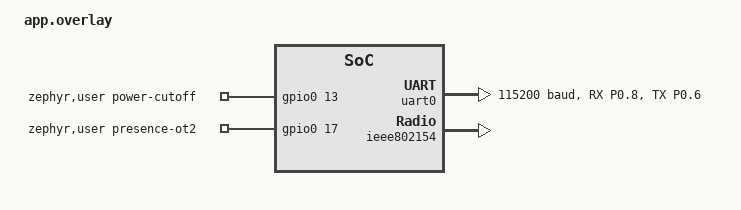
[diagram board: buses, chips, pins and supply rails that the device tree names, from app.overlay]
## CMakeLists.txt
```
# CMakeLists.txt for OpenThread SED + Home Assistant MQTT mmWave Presence Sensor (HLK-LD2410S)
cmake_minimum_required(VERSION 3.20.0)

list(APPEND BOARD_ROOT ${CMAKE_CURRENT_SOURCE_DIR})

if(EXISTS "${CMAKE_CURRENT_SOURCE_DIR}/local.conf")
    list(APPEND EXTRA_CONF_FILE "${CMAKE_CURRENT_SOURCE_DIR}/local.conf")
endif()

find_package(Zephyr HINTS $ENV{ZEPHYR_BASE})
project(presence-sensor-nrf)

target_include_directories(app PRIVATE
    src
)

target_sources(app PRIVATE
    src/main.cpp
    src/app_task.cpp
    src/battery_monitor.cpp
    src/ld2410s_proto.cpp
    src/sensor_ld2410s.cpp
    src/bthome_proto.cpp
    src/ha_mqtt_proto.cpp
    src/ota_updater.cpp
    src/thread_mqtt_publisher.cpp
    src/status_led.cpp
)

target_sources_ifdef(CONFIG_APP_DEBUG_KEEP_ALIVE app PRIVATE src/debug_fatal.c)
```

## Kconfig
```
#
# Copyright (c) 2026 Craig McLean
# OpenThread SED + Home Assistant MQTT mmWave Presence Sensor (HLK-LD2410S / HLK-LD2410C) Kconfig
#

mainmenu "OpenThread SED + Home Assistant MQTT mmWave Presence Sensor"

choice APP_RADAR_MODEL
	prompt "Hi-Link 24 GHz mmWave radar module model"
	default APP_RADAR_LD2410S

config APP_RADAR_LD2410S
	bool "HLK-LD2410S (3.3 V ultra-low-power, 115200 baud, 20x20 mm)"
	help
	  Hi-Link HLK-LD2410S 24 GHz ultra-low-power radar module powered from
	  3.3 V (P0.13 high-drive GPIO or 3V3), communicating at 115200 8N1 using
	  command 0x0070/0x007A and 5-byte minimal (6E..62) or standard frames,
	  with 0.70 m per range gate.

config APP_RADAR_LD2410C
	bool "HLK-LD2410C (5 V USB-C powered, 256000 baud, 16x22 mm)"
	help
	  Hi-Link HLK-LD2410C 24 GHz presence radar module powered from 5 V VBUS
	  (constant USB-C connection), communicating at 256000 8N1 (with automatic
	  115200 baud fallback) using command 0x0060 and standard/engineering
	  frames (F4 F3 F2 F1 .. AA .. 55 00 F8 F7 F6 F5), with 0.75 m per gate.

endchoice

config APP_ALWAYS_USB_POWERED
	bool "Device is permanently USB-powered (disable battery/SED power-saving handicaps)"
	default y if APP_RADAR_LD2410C
	default n
	help
	  Enable when the board/sensor assembly is permanently powered from 5 V USB-C.
	  Disables Sleepy End Device (SED) radio duty-cycling in favor of an always-on
	  OpenThread Minimal End Device (MED, mRxOnWhenIdle=true), keeps UART0 active
	  continuously at 100 ms (10 Hz) real-time frame polling, skips battery SAADC
	  power-gating delays, and enables wireless MQTT Firmware Over-The-Air (FOTA).

config APP_HEARTBEAT_INTERVAL_SEC
	int "Periodic idle MQTT state refresh interval (seconds)"
	default 300
	help
	  Interval between periodic Home Assistant MQTT state refreshes when no
	  occupancy edge transitions occur. Occupancy state changes are always
	  transmitted immediately via fast-polled OpenThread MQTT publish.

config APP_THREAD_DATASET_TLV_HEX
	string "OpenThread Active Operational Dataset TLV hex string"
	default ""
	help
	  Active Operational Dataset TLV hex string for the local Thread network
	  (set in gitignored local.conf; never commit network keys to git).

config APP_MQTT_BROKER_IPV4
	string "Home Assistant Mosquitto MQTT broker IPv4 address (translated via NAT64)"
	default "192.168.41.250"
	help
	  IPv4 address of the Home Assistant MQTT broker. Translated to an IPv6
	  address at runtime using the OpenThread Border Router's /96 NAT64 prefix.

config APP_MQTT_BROKER_PORT
	int "Home Assistant MQTT broker TCP port"
	range 1 65535
	default 1883
	help
	  TCP port of the Home Assistant Mosquitto MQTT broker.

config APP_MQTT_USERNAME
	string "Home Assistant MQTT broker username"
	default ""
	help
	  MQTT broker username (set in gitignored local.conf).

config APP_MQTT_PASSWORD
	string "Home Assistant MQTT broker password"
	default ""
	help
	  MQTT broker password (set in gitignored local.conf; never commit to git).

config APP_MQTT_KEEPALIVE_SEC
	int "MQTT keepalive interval (seconds)"
	range 30 3600
	default 300
	help
	  MQTT keepalive interval in seconds for the persistent TCP/NAT64 session.

config APP_RADAR_POLL_INTERVAL_MS
	int "Fast UART radar poll interval for sub-second presence & distance updates (ms)"
	range 100 10000
	default 400
	help
	  Periodic interval in milliseconds at which uart0 wakes briefly (~60 ms at
	  8.0 Hz radar report rate) to sample HLK-LD2410S presence, motion, and
	  distance. Enables < 300 ms bathroom light-trigger latency even on 4-wire
	  hookups where OT2 (P0.17) is not wired.

config APP_OCCUPIED_DISTANCE_POLL_SEC
	int "Occupied target distance refresh interval (seconds)"
	range 1 300
	default 5
	help
	  Legacy/background seconds-granularity poll interval when OT2 is wired.

config APP_BATTERY_SAMPLE_INTERVAL_SEC
	int "Battery voltage sampling interval (seconds)"
	default 3600
	help
	  Interval between SAADC VDDH/5 battery voltage measurements.

config APP_RADAR_MAX_GATE
	int "HLK-LD2410S farthest detection distance gate (0.7 m per gate)"
	range 1 16
	default 3
	help
	  Sets the HLK-LD2410S farthest detection gate (0.70 m per gate).
	  Gate 3 = 2.10 m, sized for a ~3 m^3 bathroom (~1.5 x 1.5 x 2.2 m) so
	  radar energy does not penetrate drywall or doors into adjacent hallways.

config APP_RADAR_MIN_GATE
	int "HLK-LD2410S nearest detection distance gate"
	range 0 15
	default 0
	help
	  Sets the HLK-LD2410S nearest detection gate (0 = 0.0 m).

config APP_RADAR_MAX_DISTANCE_MM
	int "Maximum valid target distance boundary (mm)"
	range 500 6000
	default 2950 if APP_RADAR_LD2410C
	default 2100
	help
	  Clamps radar targets beyond this distance (mm) to Unoccupied so far-wall
	  or hallway reflections beyond the room boundary are ignored (2950 mm for
	  a 3.0 m office with HLK-LD2410C; 2100 mm for a 3 m^3 bathroom with LD2410S).

config APP_RADAR_HOLD_S
	int "Unoccupied delay / hold time (seconds)"
	range 10 600
	default 180 if APP_RADAR_LD2410C
	default 30
	help
	  Time in seconds occupancy remains asserted after the last detected motion
	  or breathing signature clears (180 s default for seated office desk work on
	  HLK-LD2410C; 30 s default for walk-in bathroom on HLK-LD2410S).

choice APP_BATTERY_SENSE
	prompt "Battery voltage sense method"
	default APP_BATTERY_SENSE_VDDH

config APP_BATTERY_SENSE_VDDH
	bool "Internal VDDH/5"
	help
	  Use when the 18650 cell is wired to the B+/BAT pad, which feeds the
	  nRF52840 VDDH pin directly (nice!nano v2 and SuperMini). No external
	  parts. Note that on the SuperMini VDDH rises while USB is charging.

config APP_BATTERY_SENSE_DIVIDER
	bool "External resistor divider on an analog input"
	help
	  The SuperMini's on-board divider is wired to P0.24, which is not an
	  analog input, so this needs an external divider.

endchoice

if APP_BATTERY_SENSE_DIVIDER

config APP_BATTERY_DIVIDER_AIN
	int "SAADC analog input (AINx) the divider midpoint is wired to"
	range 0 7
	default 5
	help
	  AIN0=P0.02 AIN1=P0.03 AIN2=P0.04 AIN3=P0.05
	  AIN4=P0.28 AIN5=P0.29 AIN6=P0.30 AIN7=P0.31

config APP_BATTERY_DIVIDER_R_TOP_OHMS
	int "Divider resistor from battery to midpoint (ohms)"
	default 806000

config APP_BATTERY_DIVIDER_R_BOTTOM_OHMS
	int "Divider resistor from midpoint to GND (ohms)"
	default 2000000

endif # APP_BATTERY_SENSE_DIVIDER

config APP_DEBUG_KEEP_ALIVE
	bool "Keep running after fatal errors, asserts and abort() (debug only)"
	help
	  Aborts only the failing thread so its error report can still be
	  logged. Never enable in a deployed build.

source "Kconfig.zephyr"
```

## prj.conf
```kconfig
# OpenThread SED + Home Assistant MQTT mmWave Presence Sensor (HLK-LD2410S) Configuration
CONFIG_CPP=y
CONFIG_STD_CPP20=y
CONFIG_REQUIRES_FULL_LIBCPP=y

# Hardware Peripherals
CONFIG_GPIO=y
CONFIG_SERIAL=y
CONFIG_UART_INTERRUPT_DRIVEN=y
CONFIG_ADC=y
CONFIG_ADC_NRFX_SAADC=y
CONFIG_HWINFO=y

# Power Management (suspends uart0 UARTE0 between radar distance reads via pm_device_action_run;
# keep CONFIG_PM_DEVICE_RUNTIME=n so uarte_nrfx_isr_int does not call nrf_uarte_disable on RX IRQ)
CONFIG_PM_DEVICE=y
CONFIG_PM_DEVICE_RUNTIME=n
CONFIG_POWEROFF=y

# Logging & console disabled in release builds for battery life.
# uart0 is used exclusively for HLK-LD2410S communication and is suspended
# via PM_DEVICE_ACTION_SUSPEND during idle sleep.
# For bring-up logs over USB CDC ACM, build with:
#   -DEXTRA_CONF_FILE=debug.conf -DEXTRA_DTC_OVERLAY_FILE=debug.overlay
CONFIG_LOG=n
CONFIG_CONSOLE=n
CONFIG_UART_CONSOLE=n
CONFIG_BOOT_BANNER=n

# System Stacks & Heap (sized for OpenThread SED + IPv6/TCP + MQTT)
CONFIG_MAIN_STACK_SIZE=6144
CONFIG_SYSTEM_WORKQUEUE_STACK_SIZE=4096
CONFIG_HEAP_MEM_POOL_SIZE=16384

# Flash, NVS & Bootloader Output (UF2 at 0x1000 for nice!nano v2 / SuperMini nRF52840)
CONFIG_BOOTLOADER_MCUBOOT=n
CONFIG_BUILD_OUTPUT_UF2=y
CONFIG_BUILD_OUTPUT_HEX=y
CONFIG_USE_DT_CODE_PARTITION=y
CONFIG_FLASH=y
CONFIG_FLASH_PAGE_LAYOUT=y
CONFIG_FLASH_MAP=y
CONFIG_NVS=y
CONFIG_SETTINGS=y
CONFIG_SETTINGS_NVS=y

# OpenThread 1.3 Sleepy End Device (SED) + NAT64 + Home Assistant MQTT over IPv6/TCP
CONFIG_BT=n
CONFIG_NETWORKING=y
CONFIG_NET_L2_OPENTHREAD=y
CONFIG_OPENTHREAD_NORDIC_LIBRARY_COMMON=y
CONFIG_OPENTHREAD_THREAD_VERSION_1_3=y
CONFIG_OPENTHREAD_MTD=y
CONFIG_OPENTHREAD_MTD_SED=y
CONFIG_OPENTHREAD_POLL_PERIOD=5000
CONFIG_OPENTHREAD_DEFAULT_TX_POWER=8
CONFIG_OPENTHREAD_MANUAL_START=y
CONFIG_OPENTHREAD_DNS_CLIENT=y
CONFIG_OPENTHREAD_CUSTOM_PARAMETERS="OPENTHREAD_CONFIG_NAT64_CLIENT_ENABLE=1"

CONFIG_NET_IPV6=y
CONFIG_NET_IPV4=n
CONFIG_NET_IPV6_NBR_CACHE=n
CONFIG_NET_IPV6_MLD=n
CONFIG_NET_TCP=y
CONFIG_NET_UDP=y
CONFIG_NET_SOCKETS=y
CONFIG_MQTT_LIB=y
CONFIG_NET_PKT_RX_COUNT=32
CONFIG_NET_PKT_TX_COUNT=32
CONFIG_NET_BUF_RX_COUNT=64
CONFIG_NET_BUF_TX_COUNT=64

# Hardening & Diagnostics
CONFIG_RESET_ON_FATAL_ERROR=y
CONFIG_THREAD_NAME=y
CONFIG_MPU_STACK_GUARD=y
```

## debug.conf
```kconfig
# Debug overlay: logs over a USB CDC ACM serial port (no USB-serial adapter needed).
# Keeps the USB peripheral and logging active - several hundred uA, do not deploy on battery.
# Usage: west build ... -- -DEXTRA_CONF_FILE=debug.conf -DEXTRA_DTC_OVERLAY_FILE=debug.overlay
# On macOS: screen /dev/cu.usbmodem* 115200
CONFIG_USB_DEVICE_STACK=y
CONFIG_USB_DEVICE_INITIALIZE_AT_BOOT=y
CONFIG_USB_DEVICE_PRODUCT="Presence Sensor Debug"
CONFIG_USB_DEVICE_PID=0x0002
CONFIG_USB_DEVICE_LOG_LEVEL_OFF=y
CONFIG_USB_CDC_ACM_LOG_LEVEL_OFF=y
CONFIG_SERIAL=y
CONFIG_UART_LINE_CTRL=y
CONFIG_CONSOLE=y
CONFIG_UART_CONSOLE=y
CONFIG_PRINTK=y
CONFIG_LOG=y
CONFIG_LOG_MODE_DEFERRED=y
CONFIG_LOG_DEFAULT_LEVEL=3
CONFIG_APP_DEBUG_KEEP_ALIVE=y
CONFIG_RESET_ON_FATAL_ERROR=n
CONFIG_LOG_BUFFER_SIZE=16384
CONFIG_CBPRINTF_FP_SUPPORT=y
```

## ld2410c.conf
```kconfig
#
# Copyright (c) 2026 Craig McLean
# Overlay configuration for Hi-Link HLK-LD2410C (5 V USB-C powered, 256000 baud, 16x22 mm)
#
# Build with:
#   west build --no-sysbuild -b nice_nano/nrf52840 -p always -- -DEXTRA_CONF_FILE="local.conf;ld2410c.conf"
#

CONFIG_APP_RADAR_LD2410C=y
CONFIG_APP_ALWAYS_USB_POWERED=y

# Always-on OpenThread Minimal End Device (MED: RxOnWhenIdle=true, zero sleepy parent-poll latency)
CONFIG_OPENTHREAD_MTD_SED=n

# 10 Hz (100 ms) real-time radar processing matching HLK-LD2410C native 10 Hz output rate
CONFIG_APP_RADAR_POLL_INTERVAL_MS=100

# Office geometry: 3.0 m max wall distance (0-indexed Gates 0..3 = 0.00..3.00 m), ~1.0 m seated desk position, 180 s (3 min) hold
CONFIG_APP_RADAR_MAX_GATE=3
CONFIG_APP_RADAR_MAX_DISTANCE_MM=2950
CONFIG_APP_RADAR_HOLD_S=180

# 180 s MQTT keepalive on always-powered Thread MED (tolerates transient 6LoWPAN/NAT64 jitter)
CONFIG_APP_MQTT_KEEPALIVE_SEC=180

# Enable flash write access for wireless MQTT FOTA self-update
CONFIG_MPU_ALLOW_FLASH_WRITE=y
```

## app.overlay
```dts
/*
 * Copyright (c) 2026 Craig McLean
 * Devicetree overlay for BTHome v2 BLE mmWave Presence Sensor (HLK-LD2410S)
 *
 * Pinout on SuperMini nRF52840 (nice!nano v2 clone):
 *   - P0.13 (VCC switch): Continuous 3.3V supply to HLK-LD2410S (cut off at <= 3.0V)
 *   - P0.17 (017 / D2):   HLK-LD2410S OT2 digital presence output (GPIO_INT_EDGE_BOTH)
 *   - P0.08 (008 / D0):   uart0 RX <- HLK-LD2410S TX (115200 8N1)
 *   - P0.06 (006 / D1):   uart0 TX -> HLK-LD2410S RX (115200 8N1)
 */

/ {
    chosen {
        /delete-property/ zephyr,console;
        /delete-property/ zephyr,shell-uart;
        /delete-property/ zephyr,uart-mcumgr;
        zephyr,ieee802154 = &ieee802154;
        zephyr,settings-partition = &storage_partition;
    };

    zephyr,user {
        /* External VCC Power Cutoff: Pin 13 (P0.13), held HIGH in System ON */
        power-cutoff-gpios = <&gpio0 13 GPIO_ACTIVE_HIGH>;
        /* HLK-LD2410S OT2 Presence Pin: P0.17 (D2), active HIGH with pull-down */
        presence-ot2-gpios = <&gpio0 17 (GPIO_ACTIVE_HIGH | GPIO_PULL_DOWN)>;
    };
};

/*
 * Explicit uart0 pinctrl matching soldered wiring:
 *   - P0.08 (008 / D0): UART_RX <- HLK-LD2410S OT1 (TX)
 *   - P0.06 (006 / D1): UART_TX -> HLK-LD2410S RX
 */
&pinctrl {
    uart0_default: uart0_default {
        group1 {
            psels = <NRF_PSEL(UART_RX, 0, 8)>;
            bias-pull-up;
        };
        group2 {
            psels = <NRF_PSEL(UART_TX, 0, 6)>;
        };
    };

    uart0_sleep: uart0_sleep {
        group1 {
            psels = <NRF_PSEL(UART_RX, 0, 8)>,
                    <NRF_PSEL(UART_TX, 0, 6)>;
            low-power-enable;
        };
    };
};

/*
 * HLK-LD2410S UART interface (115200 8N1 on P0.06 TX / P0.08 RX).
 * Explicitly suspended via pm_device_action_run(PM_DEVICE_ACTION_SUSPEND)
 * during System ON sleep so UARTE0 and the 64 MHz HFCLK draw 0 uA when idle.
 */
&uart0 {
    compatible = "nordic,nrf-uarte";
    status = "okay";
    current-speed = <115200>;
    pinctrl-0 = <&uart0_default>;
    pinctrl-1 = <&uart0_sleep>;
    pinctrl-names = "default", "sleep";
};

/* Disable unused peripherals for minimal sleep leakage */
&i2c0 {
    status = "disabled";
};

/* Enable IEEE 802.15.4 radio for OpenThread Sleepy End Device (SED) */
&ieee802154 {
    status = "okay";
};
```

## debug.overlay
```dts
/* Debug overlay: route the console and logs to a USB CDC ACM serial port. Use with debug.conf. */
/ {
    chosen {
        zephyr,console = &cdc_acm_uart0;
    };
};

&zephyr_udc0 {
    status = "okay";
    cdc_acm_uart0: cdc_acm_uart0 {
        compatible = "zephyr,cdc-acm-uart";
    };
};
```

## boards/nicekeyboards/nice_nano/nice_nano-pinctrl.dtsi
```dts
/*
 * Pin control configuration for nice!nano v2 / SuperMini nRF52840
 */

&pinctrl {
    uart0_default: uart0_default {
        group1 {
            psels = <NRF_PSEL(UART_RX, 0, 8)>;
            bias-pull-up;
        };
        group2 {
            psels = <NRF_PSEL(UART_TX, 0, 6)>;
        };
    };

    uart0_sleep: uart0_sleep {
        group1 {
            psels = <NRF_PSEL(UART_RX, 0, 8)>,
                   <NRF_PSEL(UART_TX, 0, 6)>;
            low-power-enable;
        };
    };

    i2c0_default: i2c0_default {
        group1 {
            psels = <NRF_PSEL(TWIM_SDA, 0, 17)>,
                   <NRF_PSEL(TWIM_SCL, 0, 20)>;
            bias-pull-up;
        };
    };

    i2c0_sleep: i2c0_sleep {
        group1 {
            psels = <NRF_PSEL(TWIM_SDA, 0, 17)>,
                   <NRF_PSEL(TWIM_SCL, 0, 20)>;
            low-power-enable;
        };
    };

    spi1_default: spi1_default {
        group1 {
            psels = <NRF_PSEL(SPIM_SCK, 1, 13)>,
                   <NRF_PSEL(SPIM_MOSI, 0, 10)>,
                   <NRF_PSEL(SPIM_MISO, 1, 11)>;
        };
    };

    spi1_sleep: spi1_sleep {
        group1 {
            psels = <NRF_PSEL(SPIM_SCK, 1, 13)>,
                   <NRF_PSEL(SPIM_MOSI, 0, 10)>,
                   <NRF_PSEL(SPIM_MISO, 1, 11)>;
            low-power-enable;
        };
    };
};
```

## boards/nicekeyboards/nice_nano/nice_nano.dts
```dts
/*
 * Copyright (c) 2026 Craig McLean
 * Board Devicetree for nice!nano v2 / SuperMini nRF52840
 */

/dts-v1/;

#include <nordic/nrf52840_qiaa.dtsi>
#include "nice_nano-pinctrl.dtsi"

/ {
    model = "nice!nano v2 / SuperMini nRF52840";
    compatible = "nicekeyboards,nice_nano", "nordic,nrf52840-qiaa", "nordic,nrf52840";

    chosen {
        zephyr,code-partition = &code_partition;
        zephyr,sram = &sram0;
        zephyr,flash = &flash0;
        zephyr,console = &uart0;
        zephyr,shell-uart = &uart0;
        zephyr,uart-mcumgr = &uart0;
        zephyr,ieee802154 = &ieee802154;
    };

    leds {
        compatible = "gpio-leds";
        blue_led: led_0 {
            gpios = <&gpio0 15 GPIO_ACTIVE_HIGH>;
            label = "Blue LED";
        };
    };

    buttons {
        compatible = "gpio-keys";
    };

    aliases {
        led0 = &blue_led;
    };

    zephyr,user {
        /* External VCC Power Cutoff: Pin 13 (P0.13) */
        power-cutoff-gpios = <&gpio0 13 GPIO_ACTIVE_HIGH>;
    };
};

/*
 * REG1 is left in its default LDO mode. DC/DC mode needs an inductor on DCC,
 * which is not confirmed on SuperMini clones; enabling it without one stops
 * the SoC from running. With the radio mostly asleep the saving is ~1-2 uA.
 */

/* Battery channel is configured at runtime (see battery_monitor.cpp / Kconfig) */
&adc {
    status = "okay";
};

&gpiote {
    status = "okay";
};

&gpio0 {
    status = "okay";
};

&gpio1 {
    status = "okay";
};

&i2c0 {
    compatible = "nordic,nrf-twim";
    status = "okay";
    pinctrl-0 = <&i2c0_default>;
    pinctrl-1 = <&i2c0_sleep>;
    pinctrl-names = "default", "sleep";
    clock-frequency = <I2C_BITRATE_STANDARD>;
    zephyr,pm-device-runtime-auto;
};

/*
 * Disabled for battery life: an active UARTE receiver keeps the HF clock
 * running (hundreds of uA). debug.overlay re-enables it for logging.
 */
&uart0 {
    compatible = "nordic,nrf-uarte";
    status = "disabled";
    current-speed = <115200>;
    pinctrl-0 = <&uart0_default>;
    pinctrl-1 = <&uart0_sleep>;
    pinctrl-names = "default", "sleep";
};

/*
 * Disabled for battery life: debug.overlay re-enables it for USB logging.
 */
zephyr_udc0: &usbd {
    status = "disabled";
};

&ieee802154 {
    status = "okay";
};

&flash0 {
    partitions {
        compatible = "fixed-partitions";
        #address-cells = <1>;
        #size-cells = <1>;

        /*
         * This board's Adafruit UF2 bootloader (0.6.1) reports "SoftDevice: not
         * found" in INFO_UF2.TXT; without a SoftDevice it starts the app right
         * after the MBR at 0x1000. On a board whose INFO_UF2.TXT lists
         * "SoftDevice: S140 6.1.1" the app must start at 0x26000 instead.
         */
        mbr_partition: partition@0 {
            label = "mbr";
            reg = <0x00000000 0x00001000>;
        };

        code_partition: partition@1000 {
            label = "code_partition";
            reg = <0x00001000 0x000eb000>;
        };

        storage_partition: partition@ec000 {
            label = "storage";
            reg = <0x000ec000 0x00008000>;
        };

        boot_partition: partition@f4000 {
            label = "adafruit_boot";
            reg = <0x000f4000 0x0000c000>;
        };
    };
};
```

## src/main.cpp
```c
/*
 * Copyright (c) 2026 Craig McLean
 * Main Application Entry Point
 */

#include "app_task.h"
#include "status_led.h"
#include "version.h"
#include <zephyr/logging/log.h>

#if DT_NODE_HAS_COMPAT(DT_CHOSEN(zephyr_console), zephyr_cdc_acm_uart)
#include <zephyr/drivers/uart.h>
#endif

LOG_MODULE_REGISTER(app, LOG_LEVEL_INF);

int main()
{
    // First thing: solid 500 ms flash proves the application (not the UF2 bootloader) is running
    StatusLed::Instance().Init();

#if DT_NODE_HAS_COMPAT(DT_CHOSEN(zephyr_console), zephyr_cdc_acm_uart)
    // Debug build with USB console: wait (up to 10 s) for a terminal to open
    // the port so early boot logs are not lost
    const struct device *console = DEVICE_DT_GET(DT_CHOSEN(zephyr_console));
    for (int i = 0; i < 100; i++) {
        uint32_t dtr = 0;
        if (uart_line_ctrl_get(console, UART_LINE_CTRL_DTR, &dtr) == 0 && dtr) {
            break;
        }
        k_msleep(100);
    }
#endif

    LOG_INF("=========================================================");
    LOG_INF("  OpenThread SED + HA MQTT Presence Sensor v%s (SuperMini nRF52840)", APP_VERSION_STRING);
    LOG_INF("=========================================================");

    int ret = AppTask::Instance().Start();
    if (ret != 0) {
        LOG_ERR("AppTask start failed with error: %d", ret);
        return ret;
    }

    while (true) {
        k_sleep(K_FOREVER);
    }

    return 0;
}
```

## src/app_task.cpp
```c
/*
 * Copyright (c) 2026 Craig McLean
 * Application Task & Low-Power Event Loop (HLK-LD2410S + OpenThread SED + Home Assistant MQTT)
 */

#include "app_task.h"
#include "status_led.h"
#include "version.h"
#include <zephyr/logging/log.h>

LOG_MODULE_REGISTER(app_task, LOG_LEVEL_INF);

namespace {

static constexpr uint32_t kEvtOt2Edge                      = BIT(0);
static constexpr uint32_t kEvtOccupiedPoll                 = BIT(1);
static constexpr uint32_t kEvtHeartbeat                    = BIT(2);
static constexpr uint32_t kEvtBatterySample                = BIT(3);
static constexpr uint32_t kEvtBurstDone                    = BIT(4);
static constexpr uint16_t kDistanceBurstThresholdMm        = 150u;
static constexpr int64_t  kMinDistancePublishIntervalMs    = 1500;
static constexpr int64_t  kPostTransitionReassertWindowMs  = 15000;
static constexpr int64_t  kPostTransitionReassertPeriodMs  = 3200;

} // namespace

AppTask::AppTask()
    : mBatteryStatus{BatteryMonitor::VOLTAGE_NOMINAL_MV, 50, BatteryChargeLevel::OK, false},
      mLastRadarReport{Ld2410sTargetState::Unoccupied, false, false, 0, 0, true, false, 0, 0, 0, 0, 0, 0},
      mPendingEvents(ATOMIC_INIT(0)),
      mLastStateChangeMs(0),
      mLastPublishMs(0),
      mLastPublishedDistanceMm(0u),
      mLastOccupied(false),
      mLastMotion(false)
{
}

void AppTask::OnOt2EdgeStatic()
{
    Instance().NotifyOt2Edge();
}

void AppTask::OnHeartbeatTimer(struct k_timer *timer)
{
    ARG_UNUSED(timer);
    Instance().PostEvent(kEvtHeartbeat);
}

void AppTask::OnOccupiedPollTimer(struct k_timer *timer)
{
    ARG_UNUSED(timer);
    Instance().PostEvent(kEvtOccupiedPoll);
}

void AppTask::OnBatteryTimer(struct k_timer *timer)
{
    ARG_UNUSED(timer);
    Instance().PostEvent(kEvtBatterySample);
}

void AppTask::PostEvent(uint32_t eventMask)
{
    atomic_or(&mPendingEvents, static_cast<atomic_val_t>(eventMask));
    k_sem_give(&mEventSem);
}

void AppTask::NotifyOt2Edge()
{
    PostEvent(kEvtOt2Edge);
}

void AppTask::NotifyBurstComplete()
{
    PostEvent(kEvtBurstDone);
}

void AppTask::SampleBattery()
{
    BatteryStatus status{};
    if (BatteryMonitor::Instance().ReadBatteryStatus(&status) == 0) {
        mBatteryStatus = status;
    }
}

void AppTask::PublishCurrentState(bool burst)
{
    const BthomeMeasurement m = {
        .packetId   = 0, // Auto-incremented inside ThreadMqttPublisher::Publish
        .batteryPct = mBatteryStatus.percentRemaining,
        .voltageMv  = mBatteryStatus.voltageMv,
        .motion     = mLastRadarReport.motion,
        .occupancy  = mLastRadarReport.occupied,
        .distanceMm = mLastRadarReport.distanceMm,
    };

    mLastPublishMs = k_uptime_get();
    (void)mPublisher.Publish(m, burst);
}

void AppTask::HandleOt2AndDistanceUpdate(bool forceBurst, bool forcePublish)
{
    Ld2410sReport report{};
    mRadar.SampleTargetReport(&report);

    const int64_t nowMs = k_uptime_get();
    static constexpr uint16_t kMaxDistanceMm =
        static_cast<uint16_t>(CONFIG_APP_RADAR_MAX_DISTANCE_MM);
    static constexpr int64_t kOccupancyHoldWindowMs =
        static_cast<int64_t>(CONFIG_APP_RADAR_HOLD_S) * 1000;
    mMotionTracker.Update(&report, nowMs, kMaxDistanceMm, kOccupancyHoldWindowMs);
    mLastRadarReport = report;

    const Ld2410sReport rawReport = mRadar.GetLastValidReport();
    mPublisher.UpdateRadarDiag({
        .rawState         = rawReport.rawState,
        .movingEnergy     = rawReport.movingEnergy,
        .stationaryEnergy = rawReport.stationaryEnergy,
        .movingDistCm     = rawReport.movingDistanceCm,
        .stationaryDistCm = rawReport.stationaryDistanceCm,
        .detectionDistCm  = rawReport.detectionDistanceCm,
        .rxBytes          = mRadar.GetRxBytesSeen(),
        .configured       = mRadar.IsRadarConfigured(),
        .occupied         = report.occupied,
        .motion           = report.motion,
    });

    const bool stateChanged = (report.occupied != mLastOccupied) ||
                              (report.motion != mLastMotion);
    const bool occupancyEdge = (report.occupied != mLastOccupied);
    const uint16_t distDeltaMm = (report.distanceMm > mLastPublishedDistanceMm)
                                     ? (report.distanceMm - mLastPublishedDistanceMm)
                                     : (mLastPublishedDistanceMm - report.distanceMm);
    const bool significantDistChange =
        report.occupied &&
        (distDeltaMm >= kDistanceBurstThresholdMm) &&
        ((nowMs - mLastPublishMs) >= kMinDistancePublishIntervalMs);

    if (stateChanged) {
        mLastStateChangeMs = nowMs;
        mRadar.LogDiagnostics(report, forceBurst ? "ot2-edge" : "state-chg");
    } else if (forceBurst) {
        mRadar.LogDiagnostics(report, "ot2-edge");
    } else {
        static int64_t sLastDiagLogMs = 0;
        if ((nowMs - sLastDiagLogMs) >= 2000) {
            sLastDiagLogMs = nowMs;
            mRadar.LogDiagnostics(report, "diag-2s");
        }
    }

    // Re-assert recent occupancy/motion transitions every 3.2 s for 15 s on battery/SED builds;
    // skipped on always-USB-powered Thread MED builds where TCP/MQTT delivery is continuous.
    const bool shouldReassertTransition =
        !IS_ENABLED(CONFIG_APP_ALWAYS_USB_POWERED) &&
        (mLastStateChangeMs > 0) &&
        ((nowMs - mLastStateChangeMs) <= kPostTransitionReassertWindowMs) &&
        ((nowMs - mLastPublishMs) >= kPostTransitionReassertPeriodMs);

    mLastOccupied = report.occupied;
    mLastMotion   = report.motion;

    const bool shouldBurst = forceBurst ||
                             occupancyEdge ||
                             stateChanged ||
                             significantDistChange ||
                             shouldReassertTransition;
    if (shouldBurst || forcePublish) {
        mLastPublishedDistanceMm = report.distanceMm;
        PublishCurrentState(shouldBurst);
    }
}

int AppTask::Start()
{
    LOG_INF("Starting OpenThread SED + Home Assistant MQTT mmWave Presence Sensor v%s (build %d)",
            APP_VERSION_STRING, APP_BUILD_NUMBER);

    k_sem_init(&mEventSem, 0, K_SEM_MAX_LIMIT);
    k_timer_init(&mHeartbeatTimer, OnHeartbeatTimer, nullptr);
    k_timer_init(&mOccupiedPollTimer, OnOccupiedPollTimer, nullptr);
    k_timer_init(&mBatteryTimer, OnBatteryTimer, nullptr);

    // 1. Initialize Battery Monitor with P0.13 LOW (radar unpowered) and configure SAADC VDDH/5
    int ret = BatteryMonitor::Instance().Init();
    if (ret != 0) {
        LOG_ERR("BatteryMonitor::Init failed (err: %d)", ret);
        StatusLed::Instance().BlinkError(2);
    }

    // Read initial unloaded battery/VBUS voltage before enabling the radar 3.3 V rail
    SampleBattery();

    // 2. Initialize OpenThread Sleepy End Device (SED) + Home Assistant MQTT Publisher
    ret = mPublisher.Init();
    if (ret != 0) {
        LOG_ERR("ThreadMqttPublisher::Init failed (err: %d)", ret);
        StatusLed::Instance().BlinkError(4);
        return ret;
    }
    PublishCurrentState(true);

    // 3. Enable P0.13 3.3 V VCC rail and initialize HLK-LD2410S (P0.17 OT2 + uart0 config + auto pin-swap probe)
    (void)BatteryMonitor::Instance().SetSensorPower(true);
    ret = mRadar.Init(OnOt2EdgeStatic);
    if (ret != 0) {
        LOG_ERR("SensorLd2410s::Init failed (err: %d)", ret);
        StatusLed::Instance().BlinkError(3);
    }

    // Ensure P0.15 status LED is strictly OFF before entering the low-power event loop
    StatusLed::Instance().Set(false);

    // 4. Perform initial radar sample and queue/publish updated state
    HandleOt2AndDistanceUpdate(true, true);

    // 5. Start periodic low-power timers (400 ms sub-second radar UART poll + heartbeat + battery)
    k_timer_start(&mOccupiedPollTimer,
                   K_MSEC(CONFIG_APP_RADAR_POLL_INTERVAL_MS),
                   K_MSEC(CONFIG_APP_RADAR_POLL_INTERVAL_MS));
    k_timer_start(&mHeartbeatTimer,
                   K_SECONDS(CONFIG_APP_HEARTBEAT_INTERVAL_SEC),
                   K_SECONDS(CONFIG_APP_HEARTBEAT_INTERVAL_SEC));
    k_timer_start(&mBatteryTimer,
                   K_SECONDS(CONFIG_APP_BATTERY_SAMPLE_INTERVAL_SEC),
                   K_SECONDS(CONFIG_APP_BATTERY_SAMPLE_INTERVAL_SEC));

    LOG_INF("Entering System ON low-power event loop (poll=%dms, heartbeat=%ds, battery=%ds)",
            CONFIG_APP_RADAR_POLL_INTERVAL_MS,
            CONFIG_APP_HEARTBEAT_INTERVAL_SEC,
            CONFIG_APP_BATTERY_SAMPLE_INTERVAL_SEC);

    while (true) {
        k_sem_take(&mEventSem, K_FOREVER);

        const uint32_t events = static_cast<uint32_t>(atomic_clear(&mPendingEvents));

        if (events & kEvtBatterySample) {
            SampleBattery();
        }

        const bool forceBurst   = (events & kEvtOt2Edge) != 0u;
        const bool forcePublish = (events & kEvtHeartbeat) != 0u;

        if (events & (kEvtOt2Edge | kEvtOccupiedPoll)) {
            HandleOt2AndDistanceUpdate(forceBurst, forcePublish);
        } else if (forcePublish) {
            PublishCurrentState(false);
        }

        // Flush any queued boot/reconnect publish once Thread attaches and service MQTT keepalive
        mPublisher.ProcessBackground();
    }

    return 0;
}
```

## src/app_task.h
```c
/*
 * Copyright (c) 2026 Craig McLean
 * Application Task & Low-Power Event Loop (HLK-LD2410S + OpenThread SED + HA MQTT)
 */

#pragma once

#include <zephyr/kernel.h>
#include <zephyr/sys/atomic.h>
#include "battery_monitor.h"
#include "sensor_ld2410s.h"
#include "thread_mqtt_publisher.h"

class AppTask {
public:
    static AppTask &Instance() {
        static AppTask sInstance;
        return sInstance;
    }

    /**
     * @brief Initialize peripherals, OpenThread SED + HA MQTT publisher, and run the low-power event loop.
     */
    int Start();

    /**
     * @brief Signal from ISR or timer context that an OT2 GPIO edge occurred.
     */
    void NotifyOt2Edge();

    /**
     * @brief Signal from timer context that a burst window completed.
     */
    void NotifyBurstComplete();

private:
    AppTask();

    static void OnOt2EdgeStatic();
    static void OnHeartbeatTimer(struct k_timer *timer);
    static void OnOccupiedPollTimer(struct k_timer *timer);
    static void OnBatteryTimer(struct k_timer *timer);

    void PostEvent(uint32_t eventMask);
    void HandleOt2AndDistanceUpdate(bool forceBurst, bool forcePublish = false);
    void SampleBattery();
    void PublishCurrentState(bool burst);

    SensorLd2410s        mRadar;
    ThreadMqttPublisher  mPublisher;
    BatteryStatus        mBatteryStatus;
    Ld2410sReport        mLastRadarReport;
    Ld2410sMotionTracker mMotionTracker;
    struct k_sem         mEventSem;
    atomic_t           mPendingEvents;
    struct k_timer     mHeartbeatTimer;
    struct k_timer     mOccupiedPollTimer;
    struct k_timer     mBatteryTimer;
    int64_t            mLastStateChangeMs;
    int64_t            mLastPublishMs;
    uint16_t           mLastPublishedDistanceMm;
    bool               mLastOccupied;
    bool               mLastMotion;
};
```

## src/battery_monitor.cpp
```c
/*
 * Copyright (c) 2026 Craig McLean
 * Battery Voltage Monitor & Continuous External VCC Rail Protection
 */

#include "battery_monitor.h"
#include <string.h>
#include <hal/nrf_power.h>
#include <zephyr/logging/log.h>
#include <zephyr/logging/log_ctrl.h>
#include <zephyr/sys/poweroff.h>
#include <zephyr/dt-bindings/adc/nrf-saadc.h>
#include <zephyr/dt-bindings/adc/nrf-saadc-v3.h>

LOG_MODULE_REGISTER(battery_monitor, LOG_LEVEL_INF);

#define ZEPHYR_USER_NODE DT_PATH(zephyr_user)

static constexpr uint8_t kAdcChannelId = 0;

#if defined(CONFIG_APP_BATTERY_SENSE_VDDH)
// The cell feeds VDDH directly (B+ / BAT pad), so it is measured through the
// SAADC's internal VDDH/5 input: no external divider and no divider leakage.
// Gain 1/2 with the 0.6 V reference gives 1.2 V full scale = 6.0 V at VDDH.
static constexpr enum adc_gain kAdcGain = ADC_GAIN_1_2;
static constexpr uint8_t kAdcInput = NRF_SAADC_VDDHDIV5;
static constexpr int64_t kScaleNum = 5;
static constexpr int64_t kScaleDen = 1;
#else
// External divider: Vbat = Vpin * (Rtop + Rbottom) / Rbottom.
// Gain 1/6 with the 0.6 V reference gives 3.6 V full scale at the pin.
static constexpr enum adc_gain kAdcGain = ADC_GAIN_1_6;
static constexpr uint8_t kAdcInput = NRF_SAADC_AIN0 + CONFIG_APP_BATTERY_DIVIDER_AIN;
static constexpr int64_t kScaleNum =
    static_cast<int64_t>(CONFIG_APP_BATTERY_DIVIDER_R_TOP_OHMS) + CONFIG_APP_BATTERY_DIVIDER_R_BOTTOM_OHMS;
static constexpr int64_t kScaleDen = CONFIG_APP_BATTERY_DIVIDER_R_BOTTOM_OHMS;
#endif

BatteryMonitor::BatteryMonitor()
    : mAdcDev(DEVICE_DT_GET_OR_NULL(DT_NODELABEL(adc))),
      mCutoffGpio(GPIO_DT_SPEC_GET_OR(ZEPHYR_USER_NODE, power_cutoff_gpios, {0})),
      mAdcBuffer(0),
      mConsecutiveCutoffCount(0),
      mInitialized(false),
      mCutoffActive(false),
      mExternalPowerEnabled(false)
{
    memset(&mChannelCfg, 0, sizeof(mChannelCfg));
}

int BatteryMonitor::Init()
{
    // Step 1: Initialize Pin 13 (P0.13) Power Cutoff GPIO as INACTIVE (LOW) initially.
    // This allows the unloaded VDDH voltage to be measured and BLE advertising to start
    // before enabling the HLK-LD2410S ~70 mA cold-boot inrush via SetSensorPower(true).
    if (mCutoffGpio.port != nullptr && device_is_ready(mCutoffGpio.port)) {
        int ret = gpio_pin_configure_dt(&mCutoffGpio, GPIO_OUTPUT_INACTIVE);
        if (ret != 0) {
            LOG_ERR("Failed to configure Pin 13 power cutoff GPIO (err: %d)", ret);
            return ret;
        }
        mExternalPowerEnabled = false;
        LOG_INF("External VCC rail (P0.13) initialized LOW prior to unloaded SAADC sample");
    } else {
        LOG_WRN("Pin 13 power cutoff GPIO not defined or not ready");
    }

    // Step 2: Initialize SAADC
    if (!mAdcDev || !device_is_ready(mAdcDev)) {
        LOG_ERR("SAADC device not ready");
        return -ENODEV;
    }

    mChannelCfg.gain             = kAdcGain;
    mChannelCfg.reference        = ADC_REF_INTERNAL; // 0.6V internal bandgap
    mChannelCfg.acquisition_time = ADC_ACQ_TIME(ADC_ACQ_TIME_MICROSECONDS, 40);
    mChannelCfg.channel_id       = kAdcChannelId;
    mChannelCfg.input_positive   = kAdcInput;

    int ret = adc_channel_setup(mAdcDev, &mChannelCfg);
    if (ret != 0) {
        LOG_ERR("SAADC channel setup failed (err: %d)", ret);
        return ret;
    }

    mInitialized = true;
#if defined(CONFIG_APP_BATTERY_SENSE_VDDH)
    LOG_INF("Battery monitor initialized on internal VDDH/5");
#else
    LOG_INF("Battery monitor initialized on AIN%d with external divider", CONFIG_APP_BATTERY_DIVIDER_AIN);
#endif
    return 0;
}

bool BatteryMonitor::IsUsbVbusConnected() const
{
    return nrf_power_usbregstatus_vbusdet_get(NRF_POWER);
}

int BatteryMonitor::SetExternalPowerEnabled(bool enable)
{
    if (mCutoffGpio.port == nullptr || !device_is_ready(mCutoffGpio.port)) {
        return -ENODEV;
    }

    int ret = gpio_pin_set_dt(&mCutoffGpio, enable ? 1 : 0);
    if (ret == 0) {
        mExternalPowerEnabled = enable;
        LOG_INF("External VCC rail set to: %s", enable ? "ENABLED" : "CUT OFF");
    }
    return ret;
}

uint8_t BatteryMonitor::CalculatePercentage(uint16_t voltageMv)
{
    // Li-ion open-circuit discharge curve approximation
    if (voltageMv >= 4150) return 100;
    if (voltageMv >= 4050) return 90 + (voltageMv - 4050) / 10;
    if (voltageMv >= 3950) return 80 + (voltageMv - 3950) / 10;
    if (voltageMv >= 3850) return 70 + (voltageMv - 3850) / 10;
    if (voltageMv >= 3780) return 60 + (voltageMv - 3780) * 10 / 70;
    if (voltageMv >= 3700) return 50 + (voltageMv - 3700) * 10 / 80;
    if (voltageMv >= 3630) return 40 + (voltageMv - 3630) * 10 / 70;
    if (voltageMv >= 3550) return 30 + (voltageMv - 3550) * 10 / 80;
    if (voltageMv >= 3450) return 20 + (voltageMv - 3450) * 10 / 100;
    if (voltageMv >= 3350) return 10 + (voltageMv - 3350) * 10 / 100;
    if (voltageMv >= 3200) return 5 + (voltageMv - 3200) * 5 / 150;
    if (voltageMv >= 3000) return (voltageMv - 3000) * 5 / 200;
    return 0;
}

int BatteryMonitor::ReadMillivolts(uint16_t *outMv)
{
    struct adc_sequence sequence = {
        .options      = nullptr,
        .channels     = BIT(kAdcChannelId),
        .buffer       = &mAdcBuffer,
        .buffer_size  = sizeof(mAdcBuffer),
        .resolution   = 12,
        .oversampling = 4, // 16 samples averaged in hardware
        .calibrate    = true,
    };

    int ret = adc_read(mAdcDev, &sequence);
    if (ret != 0) {
        LOG_ERR("ADC read failed (err: %d)", ret);
        return ret;
    }

    int32_t pinMv = mAdcBuffer < 0 ? 0 : mAdcBuffer;
    ret = adc_raw_to_millivolts(adc_ref_internal(mAdcDev), kAdcGain, sequence.resolution, &pinMv);
    if (ret != 0) {
        return ret;
    }

    int64_t battMv = static_cast<int64_t>(pinMv) * kScaleNum / kScaleDen;
    *outMv = static_cast<uint16_t>(MIN(battMv, UINT16_MAX));
    return 0;
}

int BatteryMonitor::ReadBatteryStatus(BatteryStatus *outStatus)
{
    if (!mInitialized || !outStatus) {
        return -EINVAL;
    }

    uint16_t battMv = 0;
    int ret = ReadMillivolts(&battMv);
    if (ret != 0) {
        return ret;
    }

    const bool vbusConnected = IsUsbVbusConnected();

    // Confirm a low reading before acting on it (only when running on battery;
    // when USB-C is connected without a battery on B+, the TP4054 BAT node can
    // droop under the HLK-LD2410S load and must not stall or trigger System OFF).
    if (battMv <= VOLTAGE_CUTOFF_MV && !vbusConnected) {
        uint32_t sum = 0;
        int count = 0;
        for (int i = 0; i < CUTOFF_CONFIRM_SAMPLES; i++) {
            k_msleep(CUTOFF_CONFIRM_SPACING_MS);
            uint16_t mv = 0;
            if (ReadMillivolts(&mv) == 0) {
                sum += mv;
                count++;
            }
        }
        if (count > 0) {
            battMv = static_cast<uint16_t>(sum / static_cast<uint32_t>(count));
        }
        LOG_WRN("Low reading confirmed as %u mV (average of %d)", battMv, count);
    }

    outStatus->voltageMv = battMv;
    outStatus->percentRemaining = CalculatePercentage(battMv);
    outStatus->isCutoffActive = mCutoffActive;

    // Determine charge level status
    if (battMv > VOLTAGE_WARNING_MV) {
        outStatus->chargeLevel = BatteryChargeLevel::OK;
    } else if (battMv > VOLTAGE_CRITICAL_MV) {
        outStatus->chargeLevel = BatteryChargeLevel::Warning;
        LOG_WRN("Battery low: %u mV (%u%%)", battMv, outStatus->percentRemaining);
    } else {
        outStatus->chargeLevel = BatteryChargeLevel::Critical;
        LOG_WRN("Battery/VDDH reading low: %u mV (%u%%, usb_vbus=%d)",
                battMv, outStatus->percentRemaining, vbusConnected ? 1 : 0);
    }

    // Check for hard over-discharge cutoff condition (<= 3000 mV) across consecutive status checks.
    // Never enter System OFF when USB VBUS is connected (e.g. benchtop USB testing without a battery).
    if (battMv <= VOLTAGE_CUTOFF_MV && !mCutoffActive && !vbusConnected) {
        mConsecutiveCutoffCount++;
        LOG_WRN("Under-voltage sample (%u mV <= %u mV), consecutive=%d/%d",
                battMv, VOLTAGE_CUTOFF_MV, mConsecutiveCutoffCount, CUTOFF_CONSECUTIVE_READINGS);
        if (mConsecutiveCutoffCount >= CUTOFF_CONSECUTIVE_READINGS) {
            LOG_ERR("CRITICAL UNDER-VOLTAGE (%u mV <= %u mV)! Activating VCC power cutoff to protect 18650 cell.",
                    battMv, VOLTAGE_CUTOFF_MV);
            mCutoffActive = true;
            EnterSystemOff();
        }
    } else {
        mConsecutiveCutoffCount = 0;
    }

    LOG_INF("Battery: %u mV, %u%% (usb_vbus=%d)",
            battMv, outStatus->percentRemaining, vbusConnected ? 1 : 0);

    return 0;
}

void BatteryMonitor::EnterSystemOff()
{
    // Disconnect external VCC rail (powers down HLK-LD2410S); GPIO state is retained in System OFF
    SetExternalPowerEnabled(false);

    LOG_ERR("Entering nRF52840 SYSTEM OFF");
    LOG_PANIC(); // Flush deferred logs synchronously

    sys_poweroff();
    CODE_UNREACHABLE;
}
```

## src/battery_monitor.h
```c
/*
 * Copyright (c) 2026 Craig McLean
 * Battery Voltage Monitor & Continuous External VCC Rail Protection
 */

#pragma once

#include <zephyr/kernel.h>
#include <zephyr/drivers/adc.h>
#include <zephyr/drivers/gpio.h>

enum class BatteryChargeLevel : uint8_t {
    OK = 0,
    Warning = 1,
    Critical = 2
};

struct BatteryStatus {
    uint16_t voltageMv;        // Battery voltage in millivolts (e.g. 3850)
    uint8_t  percentRemaining; // 0 to 100 %
    BatteryChargeLevel chargeLevel;
    bool isCutoffActive;       // True if low voltage cutoff was triggered
};

class BatteryMonitor {
public:
    static BatteryMonitor &Instance() {
        static BatteryMonitor sInstance;
        return sInstance;
    }

    // Safety Voltage Thresholds (in mV) for raw 18650 cell
    static constexpr uint16_t VOLTAGE_MAX_MV       = 4200; // 100% full
    static constexpr uint16_t VOLTAGE_NOMINAL_MV   = 3700; // ~50%
    static constexpr uint16_t VOLTAGE_WARNING_MV   = 3400; // Low battery warning threshold
    static constexpr uint16_t VOLTAGE_CRITICAL_MV  = 3050; // Critical warning
    static constexpr uint16_t VOLTAGE_CUTOFF_MV    = 3000; // Hard cutoff threshold to prevent cell damage

    // A reading at or below the cutoff is confirmed by averaging this many
    // further readings, spaced apart, and requiring consecutive low status
    // checks so a radio-TX or radar startup inrush dip cannot power the device off.
    static constexpr int CUTOFF_CONFIRM_SAMPLES      = 8;
    static constexpr int CUTOFF_CONFIRM_SPACING_MS   = 250;
    static constexpr int CUTOFF_CONSECUTIVE_READINGS = 2;

    /**
     * @brief Initialize SAADC channel and Pin 13 (P0.13) power cutoff GPIO.
     *        Configures P0.13 LOW initially so unloaded battery voltage and BLE
     *        advertising can initialize before enabling the HLK-LD2410S rail.
     */
    int Init();

    /**
     * @brief Control external VCC rail switch (Pin 13 / P0.13).
     * @param enable true to enable external rail, false to cut off.
     */
    int SetExternalPowerEnabled(bool enable);

    /**
     * @brief Alias for SetExternalPowerEnabled() to control HLK-LD2410S 3.3V power.
     */
    int SetSensorPower(bool enable) { return SetExternalPowerEnabled(enable); }

    /**
     * @brief Query whether external VCC rail switch is currently enabled.
     */
    bool IsExternalPowerEnabled() const { return mExternalPowerEnabled; }

    /**
     * @brief Query whether USB VBUS (5V) is currently connected.
     */
    bool IsUsbVbusConnected() const;

    /**
     * @brief Read the battery voltage, compute percentage and check cutoff protection.
     * @param outStatus Pointer to BatteryStatus structure to populate.
     * @return 0 on success, negative errno on failure.
     */
    int ReadBatteryStatus(BatteryStatus *outStatus);

    /**
     * @brief Cut external VCC and enter System OFF. Does not return; only a
     *        reset (RST button) or power cycle wakes the device.
     */
    [[noreturn]] void EnterSystemOff();

    /**
     * @brief Map Li-ion open-circuit voltage (mV) to 0..100%.
     */
    static uint8_t CalculatePercentage(uint16_t voltageMv);

private:
    BatteryMonitor();

    int ReadMillivolts(uint16_t *outMv);

    const struct device *mAdcDev;
    struct gpio_dt_spec mCutoffGpio;
    struct adc_channel_cfg mChannelCfg;
    int16_t mAdcBuffer;
    int mConsecutiveCutoffCount;
    bool mInitialized;
    bool mCutoffActive;
    bool mExternalPowerEnabled;
};
```

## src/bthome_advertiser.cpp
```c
/*
 * Copyright (c) 2026 Craig McLean
 * Zephyr BLE BTHome v2 Broadcaster (Burst on State Change + Low-Power Heartbeat)
 */

#include "bthome_advertiser.h"
#include "app_task.h"
#include <string.h>
#include <zephyr/bluetooth/bluetooth.h>
#include <zephyr/bluetooth/addr.h>
#include <zephyr/drivers/hwinfo.h>
#include <zephyr/logging/log.h>

LOG_MODULE_REGISTER(bthome_adv, LOG_LEVEL_INF);

static constexpr uint8_t kAdvFlags = BT_LE_AD_GENERAL | BT_LE_AD_NO_BREDR;

BthomeAdvertiser::BthomeAdvertiser()
    : mIdentityId(BT_ID_DEFAULT),
      mPacketId(0),
      mAdvertising(false),
      mInBurstMode(false),
      mIsOccupiedOrActive(false)
{
    memset(mSvcData, 0, sizeof(mSvcData));
    memcpy(mDeviceName, "Presence-0000", sizeof("Presence-0000"));
}

void BthomeAdvertiser::OnBurstTimerExpired(struct k_timer *timer)
{
    ARG_UNUSED(timer);
    AppTask::Instance().NotifyBurstComplete();
}

int BthomeAdvertiser::Init()
{
    k_timer_init(&mBurstTimer, OnBurstTimerExpired, nullptr);

    // 1. Read factory-programmed 64-bit FICR device ID for unique BLE address & name
    uint8_t devId[16] = {};
    ssize_t devIdLen = hwinfo_get_device_id(devId, sizeof(devId));
    if (devIdLen <= 0) {
        LOG_WRN("hwinfo_get_device_id failed (%d); using fallback ID", static_cast<int>(devIdLen));
        devIdLen = 8;
    }

    BthomeProto::FormatDeviceName(devId, static_cast<size_t>(devIdLen), mDeviceName, sizeof(mDeviceName));

    // 2. Pre-create a deterministic static random BLE address from FICR device ID
    //    before bt_enable() (or after bt_enable() if default identity is used).
    bt_addr_le_t staticAddr{};
    staticAddr.type = BT_ADDR_LE_RANDOM;
    for (size_t i = 0; i < 6; ++i) {
        staticAddr.a.val[i] = devId[i % static_cast<size_t>(devIdLen)] ^
                              devId[(i + 2) % static_cast<size_t>(devIdLen)];
    }
    // Static random BLE address requires the two MSBs of the most-significant byte to be 11b (0xC0)
    staticAddr.a.val[5] |= 0xC0u;

    int ret = bt_enable(nullptr);
    if (ret != 0) {
        LOG_ERR("bt_enable failed (err: %d)", ret);
        return ret;
    }

    int idRet = bt_id_create(&staticAddr, nullptr);
    if (idRet >= 0) {
        mIdentityId = static_cast<uint8_t>(idRet);
    } else {
        mIdentityId = BT_ID_DEFAULT;
    }

    bt_set_name(mDeviceName);

    LOG_INF("BLE BTHome v2 initialized: name=%s, MAC=%02X:%02X:%02X:%02X:%02X:%02X (id=%u)",
            mDeviceName,
            staticAddr.a.val[5], staticAddr.a.val[4], staticAddr.a.val[3],
            staticAddr.a.val[2], staticAddr.a.val[1], staticAddr.a.val[0],
            mIdentityId);

    return 0;
}

int BthomeAdvertiser::ApplyAdvertisingParams(uint16_t intervalMinUnits, uint16_t intervalMaxUnits)
{
    const struct bt_data ad[] = {
        BT_DATA(BT_DATA_FLAGS, &kAdvFlags, sizeof(kAdvFlags)),
        BT_DATA(BT_DATA_SVC_DATA16, mSvcData, sizeof(mSvcData)),
    };

    const uint8_t nameLen = static_cast<uint8_t>(strlen(mDeviceName));
    const struct bt_data sd[] = {
        BT_DATA(BT_DATA_NAME_COMPLETE, mDeviceName, nameLen),
    };

    struct bt_le_adv_param param = BT_LE_ADV_PARAM_INIT(
        BT_LE_ADV_OPT_SCANNABLE | BT_LE_ADV_OPT_USE_IDENTITY,
        intervalMinUnits,
        intervalMaxUnits,
        nullptr);
    param.id = mIdentityId;

    if (mAdvertising) {
        bt_le_adv_stop();
        mAdvertising = false;
    }

    int ret = bt_le_adv_start(&param, ad, ARRAY_SIZE(ad), sd, ARRAY_SIZE(sd));
    if (ret != 0) {
        LOG_ERR("bt_le_adv_start failed (err: %d)", ret);
        return ret;
    }

    mAdvertising = true;
    return 0;
}

int BthomeAdvertiser::Publish(const BthomeMeasurement &m, bool burst)
{
    BthomeMeasurement encoded = m;
    encoded.packetId    = ++mPacketId;
    mIsOccupiedOrActive = encoded.occupancy || encoded.motion;

    BthomeProto::EncodeServiceData(encoded, mSvcData, sizeof(mSvcData));

    const struct bt_data ad[] = {
        BT_DATA(BT_DATA_FLAGS, &kAdvFlags, sizeof(kAdvFlags)),
        BT_DATA(BT_DATA_SVC_DATA16, mSvcData, sizeof(mSvcData)),
    };

    const uint8_t nameLen = static_cast<uint8_t>(strlen(mDeviceName));
    const struct bt_data sd[] = {
        BT_DATA(BT_DATA_NAME_COMPLETE, mDeviceName, nameLen),
    };

    if (burst) {
        mInBurstMode = true;
        int ret = ApplyAdvertisingParams(kBurstAdvIntervalMinUnits, kBurstAdvIntervalMaxUnits);
        k_timer_start(&mBurstTimer, K_MSEC(kBurstDurationMs), K_NO_WAIT);
        LOG_INF("BTHome burst [pkt=%u]: occ=%d mot=%d dist=%u mm bat=%u%% (%u mV)",
                encoded.packetId,
                encoded.occupancy ? 1 : 0,
                encoded.motion ? 1 : 0,
                encoded.distanceMm,
                encoded.batteryPct,
                encoded.voltageMv);
        return ret;
    }

    const uint16_t steadyMinUnits = mIsOccupiedOrActive ? kActiveAdvIntervalMinUnits : kIdleAdvIntervalMinUnits;
    const uint16_t steadyMaxUnits = mIsOccupiedOrActive ? kActiveAdvIntervalMaxUnits : kIdleAdvIntervalMaxUnits;

    if (!mAdvertising) {
        mInBurstMode = false;
        return ApplyAdvertisingParams(steadyMinUnits, steadyMaxUnits);
    }

    int ret = bt_le_adv_update_data(ad, ARRAY_SIZE(ad), sd, ARRAY_SIZE(sd));
    if (ret != 0) {
        LOG_WRN("bt_le_adv_update_data failed (err: %d); restarting advertising", ret);
        return ApplyAdvertisingParams(
            mInBurstMode ? kBurstAdvIntervalMinUnits : steadyMinUnits,
            mInBurstMode ? kBurstAdvIntervalMaxUnits : steadyMaxUnits);
    }

    LOG_INF("BTHome update [pkt=%u]: occ=%d mot=%d dist=%u mm bat=%u%% (%u mV)",
            encoded.packetId,
            encoded.occupancy ? 1 : 0,
            encoded.motion ? 1 : 0,
            encoded.distanceMm,
            encoded.batteryPct,
            encoded.voltageMv);
    return 0;
}

void BthomeAdvertiser::TransitionToIdleInterval()
{
    if (!mInBurstMode) {
        return;
    }
    mInBurstMode = false;
    const uint16_t steadyMinUnits = mIsOccupiedOrActive ? kActiveAdvIntervalMinUnits : kIdleAdvIntervalMinUnits;
    const uint16_t steadyMaxUnits = mIsOccupiedOrActive ? kActiveAdvIntervalMaxUnits : kIdleAdvIntervalMaxUnits;
    ApplyAdvertisingParams(steadyMinUnits, steadyMaxUnits);
}
```
